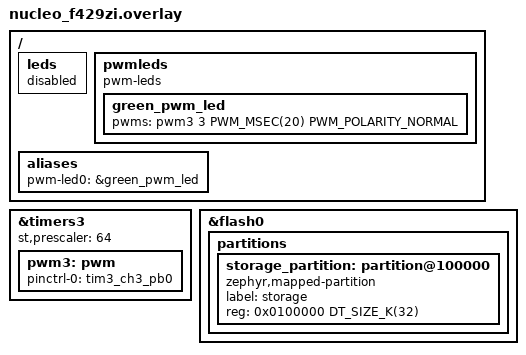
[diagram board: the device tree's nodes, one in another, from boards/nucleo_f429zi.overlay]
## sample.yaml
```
sample:
  name: BACnet Lighting Device (B-LD)

common:
  platform_allow:
    - nucleo_f429zi
  build_only: true

tests:

  bacnet-stack.sample.profile.b-ld.bacdl_none:
    tags: bacnet

  bacnet-stack.sample.profile.b-ld.bacdl_mstp:
    extra_configs:
      - CONFIG_BACDL_MSTP=y
    tags: introduction

  bacnet-stack.sample.profile.b-ld.bacdl_bip:
    extra_configs:
      - CONFIG_BACDL_BIP=y
    tags: introduction

  bacnet-stack.sample.profile.b-ld.bacdl_bip6:
    skip: true
    extra_configs:
      - CONFIG_BACDL_BIP6=y
    tags: introduction

  bacnet-stack.sample.profile.b-ld.bacdl_ethernet:
    skip: true
    extra_configs:
      - CONFIG_BACDL_ETHERNET=y
    tags: introduction
```

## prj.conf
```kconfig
# General config
#CONFIG_ASSERT=y
#CONFIG_ASSERT_LEVEL=2
#CONFIG_ASSERT_VERBOSE=y

# Compiler library config
#CONFIG_PICOLIBC=y
#CONFIG_PICOLIBC_USE_MODULE=y
#CONFIG_REQUIRES_FULL_LIBC=y
#CONFIG_MINIMAL_LIBC=y

# system
# some heap is needed for the shell
CONFIG_HEAP_MEM_POOL_SIZE=2048
CONFIG_KERNEL_MEM_POOL=y
CONFIG_MAIN_THREAD_PRIORITY=7
#CONFIG_PICOLIBC=y
CONFIG_ISR_STACK_SIZE=8192
CONFIG_MAIN_STACK_SIZE=8192
CONFIG_IDLE_STACK_SIZE=2048
CONFIG_INIT_STACKS=y

# BACnet Library
CONFIG_BACNETSTACK=y
# BACnet Library - shell
CONFIG_BACNETSTACK_BACNET_SHELL=y
CONFIG_BACNETSTACK_BACNET_BASIC_SHELL=y
CONFIG_BACAPP_PRINT_ENABLED=y
CONFIG_SHELL_STACK_SIZE=16384
# BACnet settings subsystem
CONFIG_BACNETSTACK_BACNET_SETTINGS=y
CONFIG_BACNET_SETTINGS_SHELL=y
# BACnet Library - options
CONFIG_BACNET_MAX_CHARACTER_STRING_BYTES=128
CONFIG_BACAPP_MINIMAL=y
# BACnet Library - objects
CONFIG_BACNET_BASIC_OBJECT_NETWORK_PORT=y
CONFIG_BACAPP_HOST_N_PORT=y
CONFIG_BACNET_BASIC_OBJECT_LIGHTING_OUTPUT=y
CONFIG_BACAPP_LIGHTING_COMMAND=y
# BACnet Library - server framework
CONFIG_BACNET_BASIC_SERVER=y

# BACnet Datalink Options
CONFIG_BACDL_BIP=y
CONFIG_BACDL_BIP_PORT=47808
# don't define index if you want to use the default interface
# note: with DHCP and AutoIP enabled, index 0=AutoIP, 1=DHCP
# CONFIG_BACDL_BIP_ADDRESS_INDEX=1

# networking
CONFIG_NETWORKING=y
CONFIG_NET_L2_ETHERNET=y
#CONFIG_NET_ARP=y
#CONFIG_NET_TCP=y
CONFIG_NET_UDP=y
CONFIG_NET_SHELL=y
CONFIG_NET_SOCKETS=y
CONFIG_NET_IPV4=y
CONFIG_NET_IPV4_LOG_LEVEL_DBG=n
CONFIG_NET_IF_MAX_IPV4_COUNT=2
CONFIG_NET_IF_UNICAST_IPV4_ADDR_COUNT=2
CONFIG_NET_IF_MCAST_IPV4_ADDR_COUNT=2
# Dynamic IP address
CONFIG_NET_DHCPV4=y
CONFIG_NET_DHCPV4_LOG_LEVEL_DBG=n
CONFIG_NET_IPV4_AUTO=n
CONFIG_NET_IPV4_AUTO_LOG_LEVEL_DBG=n
CONFIG_NET_ICMPV4_LOG_LEVEL_DBG=n
# read the MAC address from settings and set via net_mgmt()
CONFIG_NET_MGMT_EVENT=y
CONFIG_NET_L2_ETHERNET_MGMT=y
CONFIG_NET_CONNECTION_MANAGER=y

# Static IP address pre-configuration
#CONFIG_NET_CONFIG_SETTINGS=y
#CONFIG_NET_CONFIG_MY_IPV4_ADDR="192.0.2.1"
#CONFIG_NET_CONFIG_MY_IPV4_NETMASK="255.255.255.0"
#CONFIG_NET_CONFIG_MY_IPV4_GW="192.0.2.2"
# Network debug config
CONFIG_NET_LOG=y
CONFIG_NET_SHELL=y

#CONFIG_DNS_RESOLVER=y
#CONFIG_SLIP_STATISTICS=n

CONFIG_NET_TX_STACK_SIZE=8192
CONFIG_NET_RX_STACK_SIZE=8192

# Enable Shell, Console, and Logging features
CONFIG_CONSOLE=y
CONFIG_PRINTK=y
CONFIG_SHELL=y
CONFIG_KERNEL_SHELL=y
CONFIG_THREAD_MONITOR=y
#CONFIG_BOOT_BANNER=n
CONFIG_THREAD_NAME=y
CONFIG_DEVICE_SHELL=y
#CONFIG_POSIX_CLOCK=y
#CONFIG_DATE_SHELL=y
CONFIG_LOG=y
CONFIG_LOG_BACKEND_UART=y
CONFIG_SHELL_LOG_BACKEND=n
#CONFIG_LOG_STRDUP_BUF_COUNT=4
#CONFIG_LOG_STRDUP_MAX_STRING=96
#CONFIG_NET_CONN_LOG_LEVEL_DEFAULT=n
#CONFIG_NET_CONN_LOG_LEVEL_DBG=y
#CONFIG_NET_IF_LOG_LEVEL_DEFAULT=n
CONFIG_NET_IF_LOG_LEVEL_DBG=n
CONFIG_NET_LOG=y

# enable the thread, stack, and runtime stats
CONFIG_THREAD_ANALYZER=y
CONFIG_THREAD_STACK_INFO=y
CONFIG_THREAD_RUNTIME_STATS=y
#CONFIG_THREAD_RUNTIME_STATS_USE_TIMING_FUNCTIONS=n
#CONFIG_SCHED_THREAD_USAGE=y
#CONFIG_SCHED_THREAD_USAGE_ANALYSIS=y
CONFIG_STATS=y
CONFIG_STATS_SHELL=y

#
# Storage
#
CONFIG_FLASH=y
CONFIG_FLASH_MAP=y
#CONFIG_FLASH_PAGE_LAYOUT=y
# native_posix uses a simulated flash
#CONFIG_FLASH_SIMULATOR=y
#CONFIG_DISK_ACCESS=y.
#CONFIG_FILE_SYSTEM=y
#CONFIG_FILE_SYSTEM_LITTLEFS=y
#CONFIG_FILE_SYSTEM_SHELL=y
CONFIG_NVS=y
CONFIG_SETTINGS=y
CONFIG_SETTINGS_NVS=y
CONFIG_SETTINGS_RUNTIME=y
CONFIG_REBOOT=y
#CONFIG_SETTINGS_FILE=y
#CONFIG_SETTINGS_SHELL=y

CONFIG_TEST_RANDOM_GENERATOR=y
CONFIG_TIMER_RANDOM_GENERATOR=y

# Lighting output controlling PWM LEDs
CONFIG_PWM=y
CONFIG_LED=y
```

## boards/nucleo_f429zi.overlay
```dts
/*
 * Copyright (c) 2022 STMicroelectronics
 *
 * SPDX-License-Identifier: Apache-2.0
 */
/* FIXME: remove 'delete-node' if building with Zephyr version 4 or later
   when ST removed storage_partition from their SDK board DTS.  */
/delete-node/ &storage_partition;

/ {
  leds {
    status = "disabled";
  };

  pwmleds {
    compatible = "pwm-leds";
    green_pwm_led: green_pwm_led {
      pwms = <&pwm3 3 PWM_MSEC(20) PWM_POLARITY_NORMAL>;
    };
  };
  aliases {
    pwm-led0 = &green_pwm_led;
  };
};

&timers3 {
    status = "okay";
    st,prescaler = <64>;
    /* User LD1 GREEN */
    pwm3: pwm {
        status = "okay";
        pinctrl-0 = <&tim3_ch3_pb0>;
        pinctrl-names = "default";
    };
};

&flash0 {
  partitions {
    /*
     * nvs subsystem requires 2 sectors with a max total of 32K
     * On F4 series, the only option is to use the following
     * partition, which is compatible with mcuboot usage.
     * (limited by nvs.h: uint16_t sector_size)
     * Located in the first two 16K sectors of the second flash bank
     * (0x100000), above the firmware image which is linked at 0x0 when
     * not using mcuboot. A storage partition overlapping the firmware
     * would make the settings init fail (-EDEADLK) and erasing it would
     * erase the running firmware.
     */
    storage_partition: partition@100000 {
      compatible = "zephyr,mapped-partition";
      label = "storage";
      reg = <0x0100000 DT_SIZE_K(32)>;
    };
  };
};
```

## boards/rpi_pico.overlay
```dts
/*
 * Copyright (c) 2021 Yonatan Schachter
 *
 * SPDX-License-Identifier: Apache-2.0
 */

&flash0 {
    reg = <0x10000000 DT_SIZE_M(2)>;

    partitions {
        compatible = "fixed-partitions";
        #address-cells = <1>;
        #size-cells = <1>;

        /* Reserved memory for the second stage bootloader */
        second_stage_bootloader: partition@0 {
            label = "second_stage_bootloader";
            reg = <0x00000000 0x100>;
            read-only;
        };

        slot0_partition: partition@100 {
            label = "image-0";
            reg = <0x100 (DT_SIZE_M(1) - 0xF000)>;
        };

        storage_partition: partition@1f9000 {
            label = "storage";
            reg = <0x1F9000 0x00007000>;
        };
    };
};
```

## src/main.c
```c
/**
 * @file
 * @brief BACnet Stack sample Lighting Device (B-LD) main file
 * @author Steve Karg <skarg@users.sourceforge.net>
 * @date November 2024
 * @copyright SPDX-License-Identifier: Apache-2.0
 */
#include <zephyr/kernel.h>
#include <zephyr/device.h>
#include <zephyr/devicetree.h>
#include <zephyr/drivers/led.h>
#include <zephyr/random/random.h>
#include <zephyr/sys/util.h>
#include <stdint.h>
#include <stdlib.h>
/* BACnet Stack defines - first */
#include "bacnet/bacdef.h"
/* BACnet Stack core API */
#include "bacnet/version.h"
#include "bacnet/basic/sys/mstimer.h"
#include "bacnet/basic/sys/linear.h"
/* BACnet Stack basic device API -
   see bacnet/basic/server/bacnet_device.c for details */
#include "bacnet/basic/object/device.h"
/* BACnet Stack basic objects enabled in prj.conf */
#include "bacnet/basic/object/lo.h"
#if (BACNET_PROTOCOL_REVISION >= 17)
#include "bacnet/basic/object/netport.h"
#endif
#include "bacnet/basic/server/bacnet_basic.h"
#include "bacnet/basic/server/bacnet_port.h"

/* BACnet Stack Zephyr services */
#include <bacnet_settings/bacnet_settings.h>
#include <bacnet_osif/bacnet_lock.h>
#include <bacnet_osif/bacnet_reinit.h>
/* Logging module registration is already done in ports/zephyr/main.c */
#include <bacnet_osif/bacnet_log.h>
LOG_MODULE_DECLARE(bacnet, CONFIG_BACNETSTACK_LOG_LEVEL);

/* Default values before we get the device instance and name from settings */
static const char *Device_Name = "BACnet Lighting Device (B-LD)";
static const uint32_t Device_Instance = 260125;
/* object instances */
static const uint32_t Lighting_Instance = 1;

#define HAS_PWM_LEDS DT_HAS_COMPAT_STATUS_OKAY(pwm_leds)
#if HAS_PWM_LEDS
#define LED_PWM_NODE_ID DT_COMPAT_GET_ANY_STATUS_OKAY(pwm_leds)
#define NUM_LEDS DT_CHILD_NUM_STATUS_OKAY(LED_PWM_NODE_ID)
#endif

/**
 * @brief BACnet Lighting Output tracking value handler
 * @param object-instance [in] The object-instance number of the object
 * @param old_value [in] The value to track
 */
void BACnet_Lighting_Output_Tracking_Value_Handler(
    uint32_t object_instance, float old_value, float value)
{
    uint8_t steps = 0;

    (void)old_value;
    if (object_instance != Lighting_Instance) {
        return;
    }
    /* Tracking value are 0.0 and 1.0-100.0 normalized */
    if (isgreaterequal(value, 1.0) && islessequal(value, 100.0)) {
        steps = (uint8_t)linear_interpolate(1.0, value, 100.0, 1, 100.0);
    } else if (isgreater(value, 100.0)) {
        steps = 100;
    } else {
        steps = 0;
    }
    LOG_INF(
        "Lighting Output[%lu]: value=%f step=%u/%u",
        (unsigned long)object_instance, (double)value, (unsigned)steps,
        (unsigned)UINT8_MAX);
#if HAS_PWM_LEDS
    int err;
    uint8_t led = 0;
    const struct device *led_pwm;

    /* hardware control */
    led_pwm = DEVICE_DT_GET(LED_PWM_NODE_ID);
    if (!device_is_ready(led_pwm)) {
        LOG_ERR("Device %s is not ready", led_pwm->name);
        return;
    }
    if (!NUM_LEDS) {
        LOG_ERR("No LEDs found for %s", led_pwm->name);
        return;
    }
    if (object_instance > 0U) {
        led = object_instance - 1U;
    }
    err = led_set_brightness(led_pwm, led, steps);
    if (err < 0) {
        LOG_ERR(
            "Failed to set brightness of LED %u to %u: %d", (unsigned)led,
            (unsigned)steps, err);
    }
#else
    LOG_DBG("No pwm-leds devicetree node: skipping hardware LED update");
#endif
}

/**
 * @brief Callback data for WriteProperty restore iterator
 * @param write_function The WriteProperty function to call
 * @param context The context to pass to the WriteProperty function
 * @return true if the WriteProperty succeeded
 */
static bool
Settings_Restore_Callback(BACNET_WRITE_PROPERTY_DATA *wp_data, void *context)
{
    (void)context;
    if (wp_data == NULL) {
        return false;
    }
    if ((wp_data->object_type == OBJECT_DEVICE) &&
        (wp_data->object_instance == BACNET_MAX_INSTANCE)) {
        wp_data->object_instance = Device_Object_Instance_Number();
    }

    return Device_Write_Property(wp_data);
}

/**
 * @brief Clear any stored BACnet settings before a cold start reboot
 * @param context [in] The context to pass to the callback function
 */
static void BACnet_Lighting_Device_Coldstart_Callback(void *context)
{
    int err;

    (void)context;
    LOG_INF("COLDSTART: Clearing BACnet settings...");
    err = bacnet_settings_clear();
    if (err < 0) {
        LOG_ERR("COLDSTART: Failed to clear BACnet settings: %d", err);
    } else {
        LOG_INF("COLDSTART: Successfully cleared BACnet settings");
    }
}

/**
 * @brief BACnet Project Initialization Handler
 * @param context [in] The context to pass to the callback function
 * @note This is called from the BACnet task
 */
static void BACnet_Lighting_Device_Init_Handler(void *context)
{
    (void)context;
    LOG_INF("BACnet Stack Initialized");
    /* initialize objects with default values for this basic sample */
    Device_Set_Object_Instance_Number(Device_Instance);
    Device_Object_Name_ANSI_Init(Device_Name);
    /* lighting output object */
    Lighting_Output_Create(Lighting_Instance);
    Lighting_Output_Name_Set(Lighting_Instance, "Light-1");
    /* restore any property values previously stored via WriteProperty */
    bacnet_settings_init();
    bacnet_settings_write_property_restore(&Settings_Restore_Callback, NULL);
    /* writable property values are stored with WriteProperty.
       Set this callback after restore to prevent recursion. */
    bacnet_basic_store_callback_set(bacnet_settings_basic_store);
    /* lighting output callbacks */
    Lighting_Output_Write_Present_Value_Callback_Set(
        BACnet_Lighting_Output_Tracking_Value_Handler);
    /* done */
    LOG_INF("BACnet Device ID: %u", Device_Object_Instance_Number());
    /* set the BACnet Basic Task device object timer for lighting output use */
    bacnet_basic_task_object_timer_set(10UL);
    bacnet_reinitialize_device_init(CONFIG_BACNET_REINIT_REBOOT_DELAY);
    srand(sys_rand32_get());
}

/**
 * @brief BACnet Project Task Handler
 * @param context [in] The context to pass to the callback function
 * @note This is called from the BACnet task
 */
static void BACnet_Lighting_Device_Task_Handler(void *context)
{
    bacnet_reinitialize_device_task(
        BACnet_Lighting_Device_Coldstart_Callback, context);
}

int main(void)
{
    bool port_initialized = false;

    LOG_INF("BACnet Device: %s", Device_Name);
    LOG_INF("BACnet Stack Version " BACNET_VERSION_TEXT);
    LOG_INF("BACnet Stack Max APDU: %d", MAX_APDU);
    bacnet_basic_init_callback_set(BACnet_Lighting_Device_Init_Handler, NULL);
    bacnet_basic_task_callback_set(BACnet_Lighting_Device_Task_Handler, NULL);
    bacnet_lock();
    bacnet_basic_init();
    bacnet_unlock();
    for (;;) {
        k_sleep(K_MSEC(CONFIG_BACNET_BASIC_SERVER_KSLEEP));
        bacnet_lock();
        bacnet_basic_task();
        if (port_initialized) {
            bacnet_port_task();
        }
        bacnet_unlock();
        /* Port init can wait for an IPv4 address. Keep that wait outside
           the BACnet lock. */
        if (!port_initialized) {
            port_initialized = bacnet_port_init();
        }
    }

    return 0;
}
```
